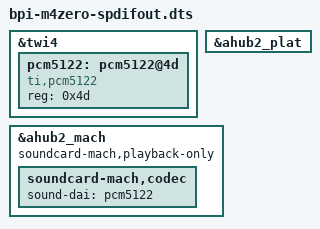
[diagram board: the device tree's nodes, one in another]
/dts-v1/;
/plugin/;

/ {
	fragment@0 {
		target = <&twi4>;
		__overlay__ {
			status = "okay";

			pcm5122: pcm5122@4d {
				compatible = "ti,pcm5122";
				reg = <0x4d>;
				#sound-dai-cells = <0>;
				status = "okay";
                       };
		};
	};

	fragment@1 {
		target = <&ahub2_plat>;
		__overlay__ {
                        status = "okay";
		};
	};

	fragment@2 {
		target = <&ahub2_mach>;
		__overlay__ {
			status = "okay";

			soundcard-mach,playback-only;
			soundcard-mach,codec {
				sound-dai = <&pcm5122>;
			};
		};
	};
};
